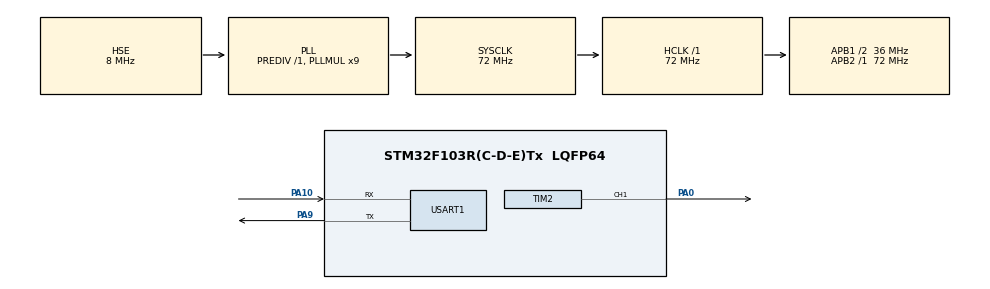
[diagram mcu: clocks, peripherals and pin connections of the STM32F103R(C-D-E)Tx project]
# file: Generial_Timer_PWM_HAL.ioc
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Mcu.Family=STM32F1
Mcu.Name=STM32F103R(C-D-E)Tx
Mcu.Package=LQFP64
NVIC.PriorityGroup=NVIC_PRIORITYGROUP_4
PA0-WKUP.Signal=S_TIM2_CH1_ETR
PA10.Mode=Asynchronous
PA10.Signal=USART1_RX
PA13.Mode=Serial_Wire
PA13.Signal=SYS_JTMS-SWDIO
PA14.Mode=Serial_Wire
PA14.Signal=SYS_JTCK-SWCLK
PA9.Mode=Asynchronous
PA9.Signal=USART1_TX
PC14-OSC32_IN.Mode=LSE-External-Oscillator
PC14-OSC32_IN.Signal=RCC_OSC32_IN
PC15-OSC32_OUT.Mode=LSE-External-Oscillator
PC15-OSC32_OUT.Signal=RCC_OSC32_OUT
PD0-OSC_IN.Mode=HSE-External-Oscillator
PD0-OSC_IN.Signal=RCC_OSC_IN
PD1-OSC_OUT.Mode=HSE-External-Oscillator
PD1-OSC_OUT.Signal=RCC_OSC_OUT
PD2.GPIO_Label=LIGHT
PD2.GPIO_Speed=GPIO_SPEED_FREQ_HIGH
PD2.Signal=EVENTOUT
ProjectManager.HeapSize=0x200
ProjectManager.StackSize=0x400
ProjectManager.TargetToolchain=STM32CubeIDE
RCC.AHBFreq_Value=72000000
RCC.APB1CLKDivider=RCC_HCLK_DIV2
RCC.APB1Freq_Value=36000000
RCC.APB1TimFreq_Value=72000000
RCC.APB2Freq_Value=72000000
RCC.APB2TimFreq_Value=72000000
RCC.HCLKFreq_Value=72000000
RCC.PLLMUL=RCC_PLL_MUL9
RCC.PLLSourceVirtual=RCC_PLLSOURCE_HSE
RCC.SYSCLKFreq_VALUE=72000000
RCC.SYSCLKSource=RCC_SYSCLKSOURCE_PLLCLK
RCC.USBFreq_Value=72000000
SH.S_TIM2_CH1_ETR.0=TIM2_CH1,PWM Generation1 CH1
TIM2.AutoReloadPreload=TIM_AUTORELOAD_PRELOAD_ENABLE
TIM2.Channel-PWM\ Generation1\ CH1=TIM_CHANNEL_1
TIM2.OCMode_PWM-PWM\ Generation1\ CH1=TIM_OCMODE_PWM1
TIM2.Period=500-1
TIM2.Prescaler=72-1
USART1.VirtualMode=VM_ASYNC
VP_TIM2_VS_ClockSourceINT.Mode=Internal
board=custom

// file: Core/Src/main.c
/* USER CODE BEGIN Header */
/**
  ******************************************************************************
  * @file           : main.c
  * @brief          : Main program body
  ******************************************************************************
  * @attention
  *
  * Copyright (c) 2023 STMicroelectronics.
  * All rights reserved.
  *
  * This software is licensed under terms that can be found in the LICENSE file
  * in the root directory of this software component.
  * If no LICENSE file comes with this software, it is provided AS-IS.
  *
  ******************************************************************************
  */
/* USER CODE END Header */
#include "main.h"

/* USER CODE BEGIN Includes */
#include "retarget.h"
/* USER CODE END Includes */

TIM_HandleTypeDef htim2;

UART_HandleTypeDef huart1;

void SystemClock_Config(void);
static void MX_GPIO_Init(void);
static void MX_USART1_UART_Init(void);
static void MX_TIM2_Init(void);

int main(void)
{
  /* USER CODE BEGIN 1 */
    RetargetInit(&huart1);
  /* USER CODE END 1 */

  /* MCU Configuration--------------------------------------------------------*/

  /* Reset of all peripherals, Initializes the Flash interface and the Systick. */
  HAL_Init();

  /* Configure the system clock */
  SystemClock_Config();

  /* Initialize all configured peripherals */
  MX_GPIO_Init();
  MX_USART1_UART_Init();
  MX_TIM2_Init();
  /* USER CODE BEGIN 2 */
    uint16_t lightPWDValue = 0;
    uint8_t  dir =1;
  /* USER CODE END 2 */

  /* Infinite loop */
  /* USER CODE BEGIN WHILE */
    HAL_TIM_PWM_Start(&htim2, TIM_CHANNEL_1);
    uint32_t  sysFreq = HAL_RCC_GetSysClockFreq();
    uint32_t  prescaler = htim2.Init.Prescaler;
    uint32_t  period = htim2.Init.Period;
  while (1)
  {
    /* USER CODE END WHILE */

    /* USER CODE BEGIN 3 */
      HAL_Delay(10);
      if(dir)
      {
          lightPWDValue++;
      }
      else
      {
          lightPWDValue--;
      }

      if(lightPWDValue > 500)
          dir = 0;
      if(lightPWDValue == 0)
          dir = 1;
      __HAL_TIM_SetCompare(&htim2, TIM_CHANNEL_1, lightPWDValue);
      printf("Freq: %d\t", sysFreq / prescaler /period );
      printf("Duty: %f\n", ((lightPWDValue* 1.0) / period) * 100 );
      printf("CCR=%d,", lightPWDValue);
      printf("PWM=%d,", __HAL_TIM_GET_COUNTER(&htim2) > lightPWDValue ? 0: 500);

  }
  /* USER CODE END 3 */
}

void SystemClock_Config(void)
{
  RCC_OscInitTypeDef RCC_OscInitStruct = {0};
  RCC_ClkInitTypeDef RCC_ClkInitStruct = {0};

  /** Initializes the RCC Oscillators according to the specified parameters
  * in the RCC_OscInitTypeDef structure.
  */
  RCC_OscInitStruct.OscillatorType = RCC_OSCILLATORTYPE_HSE;
  RCC_OscInitStruct.HSEState = RCC_HSE_ON;
  RCC_OscInitStruct.HSEPredivValue = RCC_HSE_PREDIV_DIV1;
  RCC_OscInitStruct.HSIState = RCC_HSI_ON;
  RCC_OscInitStruct.PLL.PLLState = RCC_PLL_ON;
  RCC_OscInitStruct.PLL.PLLSource = RCC_PLLSOURCE_HSE;
  RCC_OscInitStruct.PLL.PLLMUL = RCC_PLL_MUL9;
  if (HAL_RCC_OscConfig(&RCC_OscInitStruct) != HAL_OK)
  {
    Error_Handler();
  }

  /** Initializes the CPU, AHB and APB buses clocks
  */
  RCC_ClkInitStruct.ClockType = RCC_CLOCKTYPE_HCLK|RCC_CLOCKTYPE_SYSCLK
                              |RCC_CLOCKTYPE_PCLK1|RCC_CLOCKTYPE_PCLK2;
  RCC_ClkInitStruct.SYSCLKSource = RCC_SYSCLKSOURCE_PLLCLK;
  RCC_ClkInitStruct.AHBCLKDivider = RCC_SYSCLK_DIV1;
  RCC_ClkInitStruct.APB1CLKDivider = RCC_HCLK_DIV2;
  RCC_ClkInitStruct.APB2CLKDivider = RCC_HCLK_DIV1;

  if (HAL_RCC_ClockConfig(&RCC_ClkInitStruct, FLASH_LATENCY_2) != HAL_OK)
  {
    Error_Handler();
  }
}

static void MX_TIM2_Init(void)
{

  TIM_ClockConfigTypeDef sClockSourceConfig = {0};
  TIM_MasterConfigTypeDef sMasterConfig = {0};
  TIM_OC_InitTypeDef sConfigOC = {0};

  htim2.Instance = TIM2;
  htim2.Init.Prescaler = 72-1;
  htim2.Init.CounterMode = TIM_COUNTERMODE_UP;
  htim2.Init.Period = 500-1;
  htim2.Init.ClockDivision = TIM_CLOCKDIVISION_DIV1;
  htim2.Init.AutoReloadPreload = TIM_AUTORELOAD_PRELOAD_ENABLE;
  if (HAL_TIM_Base_Init(&htim2) != HAL_OK)
  {
    Error_Handler();
  }
  sClockSourceConfig.ClockSource = TIM_CLOCKSOURCE_INTERNAL;
  if (HAL_TIM_ConfigClockSource(&htim2, &sClockSourceConfig) != HAL_OK)
  {
    Error_Handler();
  }
  if (HAL_TIM_PWM_Init(&htim2) != HAL_OK)
  {
    Error_Handler();
  }
  sMasterConfig.MasterOutputTrigger = TIM_TRGO_RESET;
  sMasterConfig.MasterSlaveMode = TIM_MASTERSLAVEMODE_DISABLE;
  if (HAL_TIMEx_MasterConfigSynchronization(&htim2, &sMasterConfig) != HAL_OK)
  {
    Error_Handler();
  }
  sConfigOC.OCMode = TIM_OCMODE_PWM1;
  sConfigOC.Pulse = 0;
  sConfigOC.OCPolarity = TIM_OCPOLARITY_HIGH;
  sConfigOC.OCFastMode = TIM_OCFAST_DISABLE;
  if (HAL_TIM_PWM_ConfigChannel(&htim2, &sConfigOC, TIM_CHANNEL_1) != HAL_OK)
  {
    Error_Handler();
  }
  HAL_TIM_MspPostInit(&htim2);

}

static void MX_USART1_UART_Init(void)
{

  huart1.Instance = USART1;
  huart1.Init.BaudRate = 115200;
  huart1.Init.WordLength = UART_WORDLENGTH_8B;
  huart1.Init.StopBits = UART_STOPBITS_1;
  huart1.Init.Parity = UART_PARITY_NONE;
  huart1.Init.Mode = UART_MODE_TX_RX;
  huart1.Init.HwFlowCtl = UART_HWCONTROL_NONE;
  huart1.Init.OverSampling = UART_OVERSAMPLING_16;
  if (HAL_UART_Init(&huart1) != HAL_OK)
  {
    Error_Handler();
  }

}

static void MX_GPIO_Init(void)
{
  GPIO_InitTypeDef GPIO_InitStruct = {0};

  /* GPIO Ports Clock Enable */
  __HAL_RCC_GPIOC_CLK_ENABLE();
  __HAL_RCC_GPIOD_CLK_ENABLE();
  __HAL_RCC_GPIOA_CLK_ENABLE();

  /*Configure GPIO pin : LIGHT_Pin */
  GPIO_InitStruct.Pin = LIGHT_Pin;
  GPIO_InitStruct.Mode = GPIO_MODE_AF_PP;
  GPIO_InitStruct.Speed = GPIO_SPEED_FREQ_HIGH;
  HAL_GPIO_Init(LIGHT_GPIO_Port, &GPIO_InitStruct);

  /*Configures the port and pin on which the EVENTOUT Cortex signal will be connected */
  HAL_GPIOEx_ConfigEventout(AFIO_EVENTOUT_PORT_D, AFIO_EVENTOUT_PIN_2);

  /*Enables the Event Output */
  HAL_GPIOEx_EnableEventout();

}

void Error_Handler(void)
{
  __disable_irq();
  while (1)
  {
  }
}
